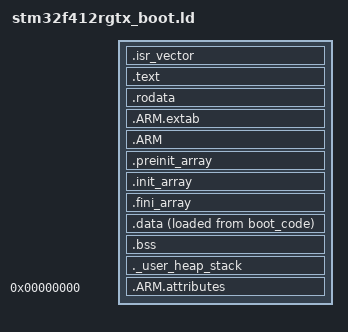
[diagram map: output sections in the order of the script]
INCLUDE stm32f412rgtx/stm32f412rgtx_memory.ld

/* Entry Point */
ENTRY(Reset_Handler)

/* Highest address of the user mode stack */
_estack = ORIGIN(ram) + LENGTH(ram); /* end of "ram" Ram type memory */

_Min_Heap_Size = 0x0; /* required amount of heap */
_Min_Stack_Size = 0x400; /* required amount of stack */

/* Sections */
SECTIONS
{
  /* The startup code into "boot_code" Rom type memory */
  .isr_vector :
  {
    . = ALIGN(4);
    KEEP(*(.isr_vector)) /* Startup code */
    . = ALIGN(4);
  } >boot_code

  /* The program code and other data into "boot_code" Rom type memory */
  .text :
  {
    . = ALIGN(4);
    *(.text)           /* .text sections (code) */
    *(.text*)          /* .text* sections (code) */
    *(.glue_7)         /* glue arm to thumb code */
    *(.glue_7t)        /* glue thumb to arm code */
    *(.eh_frame)

    KEEP (*(.init))
    KEEP (*(.fini))

    . = ALIGN(4);
    _etext = .;        /* define a global symbols at end of code */
  } >boot_code

  /* Constant data into "boot_code" Rom type memory */
  .rodata :
  {
    . = ALIGN(4);
    *(.rodata)         /* .rodata sections (constants, strings, etc.) */
    *(.rodata*)        /* .rodata* sections (constants, strings, etc.) */
    . = ALIGN(4);
  } >boot_code

  .ARM.extab   : {
    . = ALIGN(4);
    *(.ARM.extab* .gnu.linkonce.armextab.*)
    . = ALIGN(4);
  } >boot_code

  .ARM : {
    . = ALIGN(4);
    __exidx_start = .;
    *(.ARM.exidx*)
    __exidx_end = .;
    . = ALIGN(4);
  } >boot_code

  .preinit_array     :
  {
    . = ALIGN(4);
    PROVIDE_HIDDEN (__preinit_array_start = .);
    KEEP (*(.preinit_array*))
    PROVIDE_HIDDEN (__preinit_array_end = .);
    . = ALIGN(4);
  } >boot_code

  .init_array :
  {
    . = ALIGN(4);
    PROVIDE_HIDDEN (__init_array_start = .);
    KEEP (*(SORT(.init_array.*)))
    KEEP (*(.init_array*))
    PROVIDE_HIDDEN (__init_array_end = .);
    . = ALIGN(4);
  } >boot_code

  .fini_array :
  {
    . = ALIGN(4);
    PROVIDE_HIDDEN (__fini_array_start = .);
    KEEP (*(SORT(.fini_array.*)))
    KEEP (*(.fini_array*))
    PROVIDE_HIDDEN (__fini_array_end = .);
    . = ALIGN(4);
  } >boot_code

  /* Used by the startup to initialize data */
  _sidata = LOADADDR(.data);

  /* Initialized data sections into "ram" Ram type memory */
  .data :
  {
    . = ALIGN(4);
    _sdata = .;        /* create a global symbol at data start */
    *(.data)           /* .data sections */
    *(.data*)          /* .data* sections */
    *(.RamFunc)        /* .RamFunc sections */
    *(.RamFunc*)       /* .RamFunc* sections */

    . = ALIGN(4);
    _edata = .;        /* define a global symbol at data end */

  } >ram AT> boot_code

  /* Uninitialized data section into "ram" Ram type memory */
  . = ALIGN(4);
  .bss :
  {
    /* This is used by the startup in order to initialize the .bss section */
    _sbss = .;         /* define a global symbol at bss start */
    __bss_start__ = _sbss;
    *(.bss)
    *(.bss*)
    *(COMMON)

    . = ALIGN(4);
    _ebss = .;         /* define a global symbol at bss end */
    __bss_end__ = _ebss;
  } >ram

  /* User_heap_stack section, used to check that there is enough "ram" Ram  type memory left */
  ._user_heap_stack :
  {
    . = ALIGN(8);
    PROVIDE ( end = . );
    PROVIDE ( _end = . );
    . = . + _Min_Heap_Size;
    . = . + _Min_Stack_Size;
    . = ALIGN(8);
  } >ram

  /* Remove information from the compiler libraries */
  /DISCARD/ :
  {
    libc.a ( * )
    libm.a ( * )
    libgcc.a ( * )
  }

  .ARM.attributes 0 : { *(.ARM.attributes) }
}

